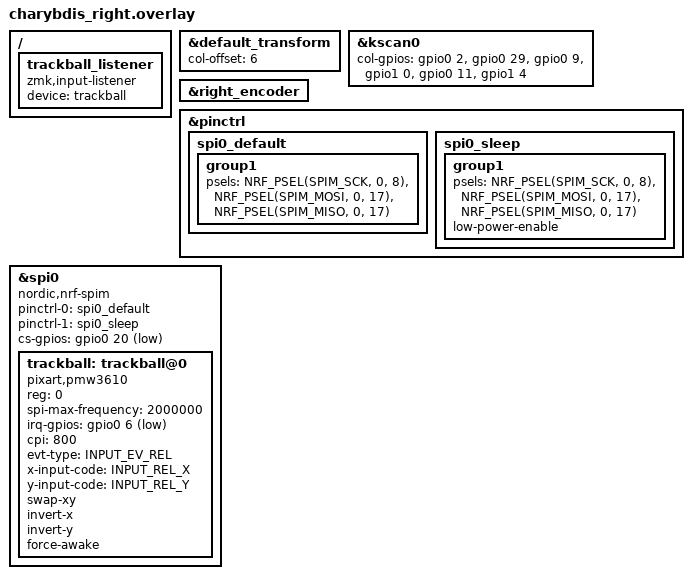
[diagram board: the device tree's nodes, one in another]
/*
 * Copyright (c) 2020 ZMK Contributors
 *
 * SPDX-License-Identifier: MIT
 */

#include "charybdis.dtsi"
#include <zephyr/dt-bindings/input/input-event-codes.h>

&default_transform {
    col-offset = <6>;
};

&kscan0 {
	col-gpios
		= <&gpio0 2 (GPIO_ACTIVE_HIGH | GPIO_PULL_DOWN)>
		, <&gpio0 29 (GPIO_ACTIVE_HIGH | GPIO_PULL_DOWN)>
		, <&gpio0 9 (GPIO_ACTIVE_HIGH | GPIO_PULL_DOWN)>
		, <&gpio1 0  (GPIO_ACTIVE_HIGH | GPIO_PULL_DOWN)>
		, <&gpio0 11 (GPIO_ACTIVE_HIGH | GPIO_PULL_DOWN)>
		, <&gpio1 4  (GPIO_ACTIVE_HIGH | GPIO_PULL_DOWN)>
		;
};
&right_encoder {
    status = "okay";
};
// trackball bus
&pinctrl {
    spi0_default: spi0_default {
        group1 {
            psels = <NRF_PSEL(SPIM_SCK, 0, 8)>,
                <NRF_PSEL(SPIM_MOSI, 0, 17)>,
                <NRF_PSEL(SPIM_MISO, 0, 17)>;
        };
    };

    spi0_sleep: spi0_sleep {
        group1 {
            psels = <NRF_PSEL(SPIM_SCK, 0, 8)>,
                <NRF_PSEL(SPIM_MOSI, 0, 17)>,
                <NRF_PSEL(SPIM_MISO, 0, 17)>;
            low-power-enable;
        };
    };
};

&spi0 {
    status = "okay";
    compatible = "nordic,nrf-spim";
    pinctrl-0 = <&spi0_default>;
    pinctrl-1 = <&spi0_sleep>;
    pinctrl-names = "default", "sleep";
    cs-gpios = <&gpio0 20 GPIO_ACTIVE_LOW>;

    trackball: trackball@0 {
        status = "okay";
        compatible = "pixart,pmw3610";
        reg = <0>;
        spi-max-frequency = <2000000>;
        irq-gpios = <&gpio0 6 (GPIO_ACTIVE_LOW | GPIO_PULL_UP)>;

        /* CPI — скорость курсора, легко правится одной строкой (200..3200, шаг 200) */
        cpi = <800>;

        /* Обязательные для нового драйвера коды осей (относительное перемещение) */
        evt-type = <INPUT_EV_REL>;
        x-input-code = <INPUT_REL_X>;
        y-input-code = <INPUT_REL_Y>;

        /* Ориентация. Старый конфиг был ORIENTATION_90 + INVERT_X.
           Если курсор поедет не в ту сторону/перепутает оси — крутить
           именно эти три флага (закомментировать/добавить invert-y). */
        swap-xy;
        invert-x;
        invert-y;

        /* Держать сенсор бодрым, пока ZMK ACTIVE; в IDLE/SLEEP — дауншифт. */
        force-awake;
    };
};
/ {
    trackball_listener {
        compatible = "zmk,input-listener";
        device = <&trackball>;
    };
};
